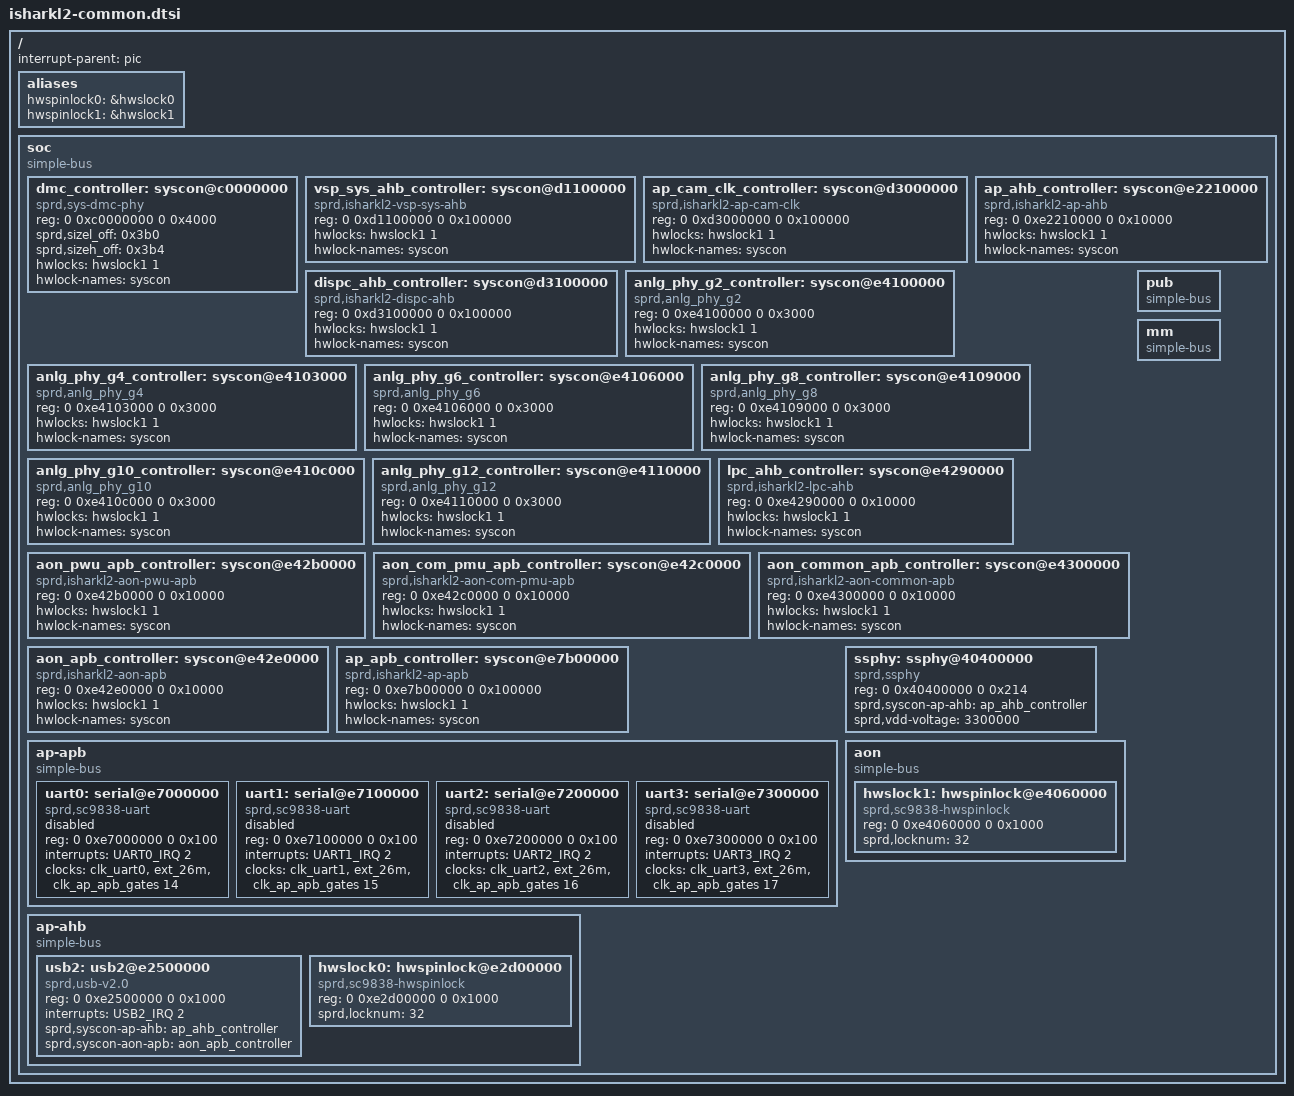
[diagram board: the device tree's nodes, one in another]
/*
 * Spreadtrum isharkl2 common DTS file
 *
 * Copyright (C) 2015, Spreadtrum Communications Inc.
 *
 * This file is licensed under a dual GPLv2 or X11 license.
 */

/ {
	interrupt-parent = <&pic>;
	#address-cells = <2>;
	#size-cells = <2>;

	aliases {
		hwspinlock0 = &hwslock0;
		hwspinlock1 = &hwslock1;
	};

	soc: soc {
		compatible = "simple-bus";
		#address-cells = <2>;
		#size-cells = <2>;
		ranges;

		dmc_controller: syscon@c0000000 {
			compatible = "sprd,sys-dmc-phy", "syscon";
			reg = <0 0xc0000000 0 0x4000>;
			sprd,sizel_off = <0x3b0>;
			sprd,sizeh_off = <0x3b4>;
			hwlocks = <&hwslock1 1>;
			hwlock-names = "syscon";
		};

		vsp_sys_ahb_controller: syscon@d1100000 {
			compatible = "sprd,isharkl2-vsp-sys-ahb", "syscon";
			reg = <0 0xd1100000 0 0x100000>;
			hwlocks = <&hwslock1 1>;
			hwlock-names = "syscon";
		};

		ap_cam_clk_controller: syscon@d3000000 {
			compatible = "sprd,isharkl2-ap-cam-clk", "syscon";
			reg = <0 0xd3000000 0 0x100000>;
			hwlocks = <&hwslock1 1>;
			hwlock-names = "syscon";
		};

		dispc_ahb_controller: syscon@d3100000 {
			compatible = "sprd,isharkl2-dispc-ahb", "syscon";
			reg = <0 0xd3100000 0 0x100000>;
			hwlocks = <&hwslock1 1>;
			hwlock-names = "syscon";
		};

		ap_ahb_controller: syscon@e2210000 {
			compatible = "sprd,isharkl2-ap-ahb", "syscon";
			reg = <0 0xe2210000 0 0x10000>;
			hwlocks = <&hwslock1 1>;
			hwlock-names = "syscon";
		};

		anlg_phy_g2_controller: syscon@e4100000 {
			compatible = "sprd,anlg_phy_g2", "syscon";
			reg = <0 0xe4100000 0 0x3000>;
			hwlocks = <&hwslock1 1>;
			hwlock-names = "syscon";
		};

		anlg_phy_g4_controller: syscon@e4103000 {
			compatible = "sprd,anlg_phy_g4", "syscon";
			reg = <0 0xe4103000 0 0x3000>;
			hwlocks = <&hwslock1 1>;
			hwlock-names = "syscon";
		};

		anlg_phy_g6_controller: syscon@e4106000 {
			compatible = "sprd,anlg_phy_g6", "syscon";
			reg = <0 0xe4106000 0 0x3000>;
			hwlocks = <&hwslock1 1>;
			hwlock-names = "syscon";
		};

		anlg_phy_g8_controller: syscon@e4109000 {
			compatible = "sprd,anlg_phy_g8", "syscon";
			reg = <0 0xe4109000 0 0x3000>;
			hwlocks = <&hwslock1 1>;
			hwlock-names = "syscon";
		};

		anlg_phy_g10_controller: syscon@e410c000 {
			compatible = "sprd,anlg_phy_g10", "syscon";
			reg = <0 0xe410c000 0 0x3000>;
			hwlocks = <&hwslock1 1>;
			hwlock-names = "syscon";
		};

		anlg_phy_g12_controller: syscon@e4110000 {
			compatible = "sprd,anlg_phy_g12", "syscon";
			reg = <0 0xe4110000 0 0x3000>;
			hwlocks = <&hwslock1 1>;
			hwlock-names = "syscon";
		};

		lpc_ahb_controller: syscon@e4290000 {
			compatible = "sprd,isharkl2-lpc-ahb", "syscon";
			reg = <0 0xe4290000 0 0x10000>;
			hwlocks = <&hwslock1 1>;
			hwlock-names = "syscon";
		};

		aon_pwu_apb_controller: syscon@e42b0000 {
			compatible = "sprd,isharkl2-aon-pwu-apb", "syscon";
			reg = <0 0xe42b0000 0 0x10000>;
			hwlocks = <&hwslock1 1>;
			hwlock-names = "syscon";
		};

		aon_com_pmu_apb_controller: syscon@e42c0000 {
			compatible = "sprd,isharkl2-aon-com-pmu-apb", "syscon";
			reg = <0 0xe42c0000 0 0x10000>;
			hwlocks = <&hwslock1 1>;
			hwlock-names = "syscon";
		};

		aon_common_apb_controller: syscon@e4300000 {
			compatible = "sprd,isharkl2-aon-common-apb", "syscon";
			reg = <0 0xe4300000 0 0x10000>;
			hwlocks = <&hwslock1 1>;
			hwlock-names = "syscon";
		};


		aon_apb_controller: syscon@e42e0000 {
			compatible = "sprd,isharkl2-aon-apb", "syscon";
			reg = <0 0xe42e0000 0 0x10000>;
			hwlocks = <&hwslock1 1>;
			hwlock-names = "syscon";
		};

		ap_apb_controller: syscon@e7b00000 {
			compatible = "sprd,isharkl2-ap-apb", "syscon";
			reg = <0 0xe7b00000 0 0x100000>;
			hwlocks = <&hwslock1 1>;
			hwlock-names = "syscon";
		};



		ap-apb {
			compatible = "simple-bus";
			#address-cells = <2>;
			#size-cells = <2>;
			ranges;

			uart0: serial@e7000000 {
				compatible = "sprd,sc9838-uart";
				reg = <0 0xe7000000 0 0x100>;
				interrupts = <UART0_IRQ 2>;
				clock-names = "uart","source","enable";
				clocks = <&clk_uart0>, <&ext_26m>, <&clk_ap_apb_gates 14>;
				status = "disabled";
			};

			uart1: serial@e7100000 {
				compatible = "sprd,sc9838-uart";
				reg = <0 0xe7100000 0 0x100>;
				interrupts = <UART1_IRQ 2>;
				clock-names = "uart","source","enable";
				clocks = <&clk_uart1>, <&ext_26m>, <&clk_ap_apb_gates 15>;
				status = "disabled";
			};

			uart2: serial@e7200000 {
				compatible = "sprd,sc9838-uart";
				reg = <0 0xe7200000 0 0x100>;
				interrupts = <UART2_IRQ 2>;
				clock-names = "uart","source","enable";
				clocks = <&clk_uart2>, <&ext_26m>, <&clk_ap_apb_gates 16>;
				status = "disabled";
			};

			uart3: serial@e7300000 {
				compatible = "sprd,sc9838-uart";
				reg = <0 0xe7300000 0 0x100>;
				interrupts = <UART3_IRQ 2>;
				clock-names = "uart","source","enable";
				clocks = <&clk_uart3>, <&ext_26m>, <&clk_ap_apb_gates 17>;
				status = "disabled";
			};
		};

		ap-ahb {
			compatible = "simple-bus";
			#address-cells = <2>;
			#size-cells = <2>;
			ranges;

			usb2: usb2@e2500000 {
				compatible  = "sprd,usb-v2.0";
				reg = <0 0xe2500000 0 0x1000>;
				interrupts = <USB2_IRQ 2>;
				/* TODO:
				 * vbus-gpios = <&pmic_eic 0 0>;
				 * usb-supply = <&vddusb>;
				 * sprd,tune-value = <0x0005af33>;
				 */
				sprd,syscon-ap-ahb = <&ap_ahb_controller>;
				sprd,syscon-aon-apb = <&aon_apb_controller>;
				/* TODO:
				 * phys = <&usbphy>;
				 */

			};

			hwslock0: hwspinlock@e2d00000{
				compatible  = "sprd,sc9838-hwspinlock";
				reg = <0 0xe2d00000 0 0x1000>;
				sprd,locknum = <32>;
			};

		};

		ssphy: ssphy@40400000 {
			compatible = "sprd,ssphy";
			reg = <0 0x40400000 0 0x214>;
			reg-names = "phy_glb_regs";
			sprd,syscon-ap-ahb = <&ap_ahb_controller>;
			sprd,vdd-voltage = <3300000>;
		};

		aon {
			compatible = "simple-bus";
			#address-cells = <2>;
			#size-cells = <2>;
			ranges;

			hwslock1: hwspinlock@e4060000{
				compatible  = "sprd,sc9838-hwspinlock";
				reg = <0 0xe4060000 0 0x1000>;
				sprd,locknum = <32>;
			};
		};

		pub {
			compatible = "simple-bus";
			#address-cells = <2>;
			#size-cells = <2>;
			ranges;

		};

		mm {
			compatible = "simple-bus";
			#address-cells = <2>;
			#size-cells = <2>;
			ranges;
		};
	};
};
